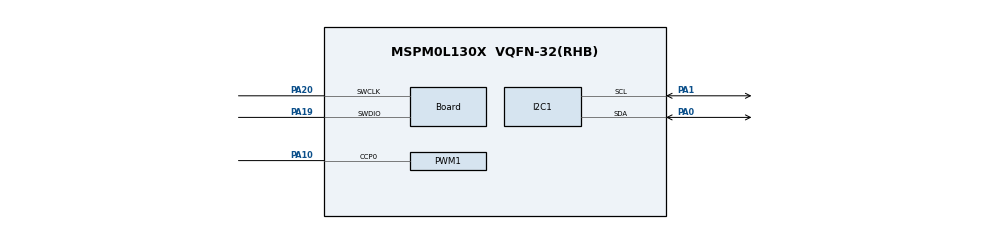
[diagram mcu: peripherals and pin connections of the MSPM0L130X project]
/**
 * @cliArgs --device "MSPM0L130X" --part "Default" --package "VQFN-32(RHB)" --product "mspm0_sdk@2.07.00.06"
 * @versions {"tool":"1.25.0+4268"}
 */

/**
 * Import the modules used in this configuration.
 */
const Board = scripting.addModule("/ti/driverlib/Board");
const I2C   = scripting.addModule("/ti/driverlib/I2C", {}, false);
const I2C1  = I2C.addInstance();
const PWM   = scripting.addModule("/ti/driverlib/PWM", {}, false);
const PWM1  = PWM.addInstance();

/**
 * Write custom configuration values to the imported modules.
 */
Board.peripheral.$assign          = "DEBUGSS";
Board.peripheral.swclkPin.$assign = "PA20";
Board.peripheral.swdioPin.$assign = "PA19";

I2C1.$name                             = "I2C";
I2C1.basicEnableController             = true;
I2C1.basicControllerBusSpeed           = 400000;
I2C1.advControllerTXFIFOTRIG           = "BYTES_1";
I2C1.intController                     = ["ARBITRATION_LOST","NACK","RXFIFO_TRIGGER","RX_DONE","TX_DONE"];
I2C1.advAnalogGlitchFilter             = "DISABLED";
I2C1.peripheral.$assign                = "I2C0";
I2C1.peripheral.sdaPin.$assign         = "PA0";
I2C1.peripheral.sclPin.$assign         = "PA1";
I2C1.sdaPinConfig.$name                = "ti_driverlib_gpio_GPIOPinGeneric0";
I2C1.sdaPinConfig.hideOutputInversion  = scripting.forceWrite(false);
I2C1.sdaPinConfig.onlyInternalResistor = scripting.forceWrite(false);
I2C1.sdaPinConfig.passedPeripheralType = scripting.forceWrite("Digital");
I2C1.sclPinConfig.$name                = "ti_driverlib_gpio_GPIOPinGeneric1";
I2C1.sclPinConfig.hideOutputInversion  = scripting.forceWrite(false);
I2C1.sclPinConfig.onlyInternalResistor = scripting.forceWrite(false);
I2C1.sclPinConfig.passedPeripheralType = scripting.forceWrite("Digital");

PWM1.$name                              = "PWM";
PWM1.ccIndex                            = [0];
PWM1.timerCount                         = 3200;
PWM1.PWM_CHANNEL_0.$name                = "ti_driverlib_pwm_PWMTimerCC0";
PWM1.PWM_CHANNEL_0.invert               = true;
PWM1.ccp0PinConfig.$name                = "ti_driverlib_gpio_GPIOPinGeneric2";
PWM1.ccp0PinConfig.direction            = scripting.forceWrite("OUTPUT");
PWM1.ccp0PinConfig.hideOutputInversion  = scripting.forceWrite(false);
PWM1.ccp0PinConfig.onlyInternalResistor = scripting.forceWrite(false);
PWM1.ccp0PinConfig.passedPeripheralType = scripting.forceWrite("Digital");
PWM1.peripheral.ccp0Pin.$assign         = "PA10";

const SYSCTL       = scripting.addModule("/ti/driverlib/SYSCTL", {}, false);
SYSCTL.clockTreeEn = true;

/**
 * Pinmux solution for unlocked pins/peripherals. This ensures that minor changes to the automatic solver in a future
 * version of the tool will not impact the pinmux you originally saw.  These lines can be completely deleted in order to
 * re-solve from scratch.
 */
PWM1.peripheral.$suggestSolution = "TIMG4";
